# TPTC1 register map
Vendor: Texas Instruments
Peripheral module from a debugger description file (folder omap36xx).
Registers are 32-bit, read-only, reset 0x0 unless marked. A register's access mark holds for its fields unless they carry their own. Offsets are as the file gives them; lines under a group give offsets from that group; [hi:lo] are bit positions; {n}, {i} and the like mark numbered series; 'fields as' and 'values as' point back to an identical list; <NAME> marks a mode.

## TPTC1
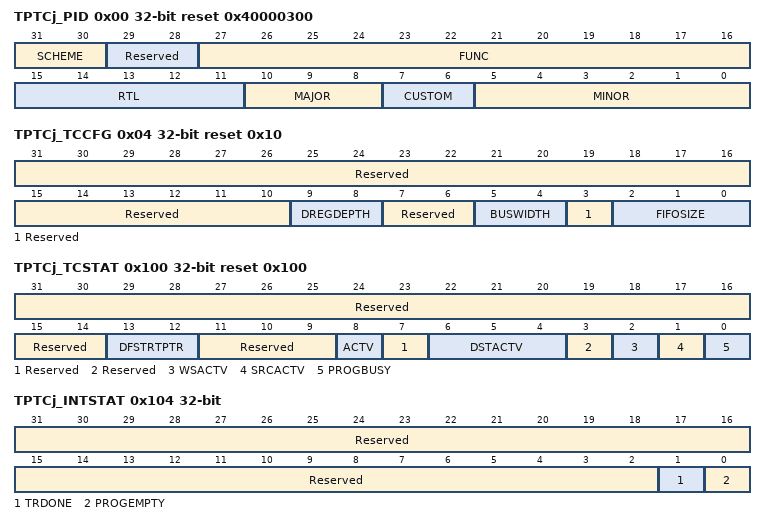
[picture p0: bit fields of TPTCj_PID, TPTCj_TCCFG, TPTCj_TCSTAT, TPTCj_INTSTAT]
0x00 TPTCj_PID access per field reset 0x40000300 (reset mask 0xFFFF07C0) — Peripheral ID Register
  [31:30] SCHEME rw — PID scheme:Used to distinguish between old ID scheme and current.Spare bit to encode future schemes EDMA uses new scheme, indicated with value of 0x1. .
  [29:28] Reserved ro — Read returns 0.
  [27:16] FUNC rw — Function indicates a software-compatible module family.
  [15:11] RTL rw — RTL version
  [10:8] MAJOR rw — Major revision
  [7:6] CUSTOM rw — Custom revision field: Not used on this version of EDMA.
  [5:0] MINOR rw — Minor revision
0x04 TPTCj_TCCFG reset 0x10 (reset mask 0xFFFFFCF8) — TC Configuration Register
  [31:10] Reserved — Read returns 0.
  [9:8] DREGDEPTH — Dst Register FIFO Depth Parameterization
    0=DREGDEPTH_0_r (1 entry); 1=DREGDEPTH_1_r (2 entries); 2=DREGDEPTH_2_r (4 entries)
  [7:6] Reserved — Read returns 0.
  [5:4] BUSWIDTH — Bus Width Parameterization
    0=BUSWIDTH_0_r (32-bit); 1=BUSWIDTH_1_r (64-bit); 2=BUSWIDTH_2_r (128-bit)
  [3] Reserved — Read returns 0.
  [2:0] FIFOSIZE — Fifo Size Parameterization
    0=FIFOSIZE_0_r (32 byte FIFO); 1=FIFOSIZE_1_r (64 byte FIFO); 2=FIFOSIZE_2_r (128 byte FIFO); 3=FIFOSIZE_3_r (256 byte FIFO); 4=FIFOSIZE_4_r (512 byte FIFO)
0x100 TPTCj_TCSTAT reset 0x100 — TC Status Register
  [31:14] Reserved — Read returns 0.
  [13:12] DFSTRTPTR — Dst FIFO Start PointerRepresents the offset to the head entry of Dst Register FIFO, in units of *entries*. Legal values = 0x0 to 0x3
  [11:9] Reserved — Read returns 0.
  [8] ACTV — Channel ActiveChannel Active is a logical-OR of each of the *BUSY/ACTV signals. The ACTV bit must remain high through the life of a TR. ACTV = 0: Channel is idle.ACTV = 1: Channel is busy.
  [7] Reserved — Read returns 0.
  [6:4] DSTACTV — Destination Active StateSpecifies the number of TRs that are resident in the Dst Register FIFO at a given instant. Legal values are constrained by the DSTREGDEPTH parameter.
    0=DSTACTV_0_r (FIFO set is empty.); {v}=DSTACTV_{v}_r (Dst FIFO contains {v} TR) (v=1..4)
  [3] Reserved — Read returns 0.
  [2] WSACTV — Write Status ActiveWSACTV = 0: Write status is not pending. Write status has been received for all previously issued write commands.WSACTV = 1: Write Status is pending. Write status has not been received for all previously issued write commands.
  [1] SRCACTV — Source Active StateSRCACTV = 0: Source Active set is idle. Any TR written to Prog Set will immediately transition to Source Active set as long as the Dst FIFO Set is not full (DSTFULL == 1).SRCACTV = 1: Source Active set is busy either performing read transfers or waiting to perform read transfers for current Transfer Request.
  [0] PROGBUSY — Program Register Set BusyPROGBUSY = 0: Prog set idle and is available for programming.PROGBUSY = 1: Prog set busy. User should poll for PROGBUSY equal to 0 prior to re-programming the Program Register set.
0x104 TPTCj_INTSTAT — Interrupt Status Register
  [31:2] Reserved — Read returns 0.
  [1] TRDONE — TR Done Event Status:TRDONE = 0: Condition not detected.TRDONE = 1: Set when TC has completed a Transfer Request. TRDONE should be set when the write status is returned for the final write of a TR. Cleared when user writes 1 to INTCLR.TRDONE register bit.
  [0] PROGEMPTY — Program Set Empty Event Status:PROGEMPTY = 0: Condition not detected.PROGEMPTY = 1: Set when Program Register set transitions to empty state. Cleared when user writes 1 to INTCLR.PROGEMPTY register bit.
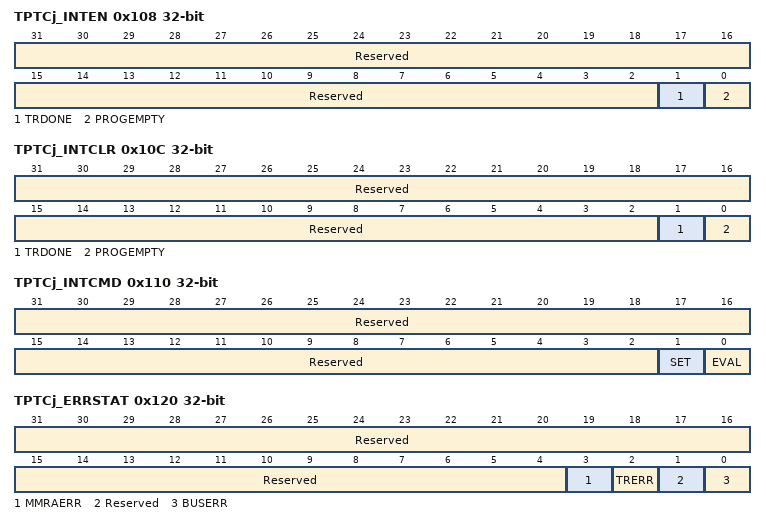
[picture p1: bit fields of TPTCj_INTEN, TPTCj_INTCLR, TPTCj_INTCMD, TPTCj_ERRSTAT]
0x108 TPTCj_INTEN rw — Interrupt Enable Register
  [31:2] Reserved — Write 0s for future compatibility.Read returns 0.
  [1] TRDONE — TR Done Event Enable:INTEN.TRDONE = 0: TRDONE Event is disabled.INTEN.TRDONE = 1: TRDONE Event is enabled,and contributes to interrupt generation
  [0] PROGEMPTY — Program Set Empty Event Enable:INTEN.PROGEMPTY = 0: PROGEMPTY Event isdisabled.INTEN.PROGEMPTY = 1: PROGEMPTY Event isenabled, and contributes to interrupt generation
0x10C TPTCj_INTCLR wo — Interrupt Clear Register
  [31:2] Reserved — Write 0s for future compatibility.
  [1] TRDONE — TR Done Event Clear:INTCLR.TRDONE = 0: Writes of 0 have no effect.INTCLR.TRDONE = 1: Write of 1 clears INTSTAT.TRDONE bit
  [0] PROGEMPTY — Program Set Empty Event Clear:INTCLR.PROGEMPTY = 0: Writes of 0 have no effect.INTCLR.PROGEMPTY = 1: Write of 1 clears INTSTAT.PROGEMPTY bit
0x110 TPTCj_INTCMD wo — Interrupt Command Register
  [31:2] Reserved — Write 0s for future compatibility.
  [1] SET — Set TPTC interrupt:Write of 1 to SET causes TPTC interrupt to be pulsed unconditionally.Writes of 0 have no effect.
  [0] EVAL — Evaluate state of TPTC interruptWrite of 1 to EVAL causes TPTC interrupt to be pulsed if any of the INTSTAT bits are set to 1.Writes of 0 have no effect.
0x120 TPTCj_ERRSTAT — Error Status Register
  [31:4] Reserved — Read returns 0.
  [3] MMRAERR — MMR Address Error:MMRAERR = 0: Condition not detected.MMRAERR = 1: User attempted to read or write to invalid address configuration memory map. (Is only be set for non-emulation accesses). No additional error information is recorded.
  [2] TRERR — TR Error:TR detected that violates FIFO Mode transfer (SAM or DAM is 1) alignment rules or has ACNT or BCNT == 0. No additional error information is recorded.
  [1] Reserved — Read returns 0.
  [0] BUSERR — Bus Error Event:BUSERR = 0: Condition not detected.BUSERR = 1: TC has detected an error code on the write response bus or read response bus. Error information is stored in Error Details Register (ERRDET).
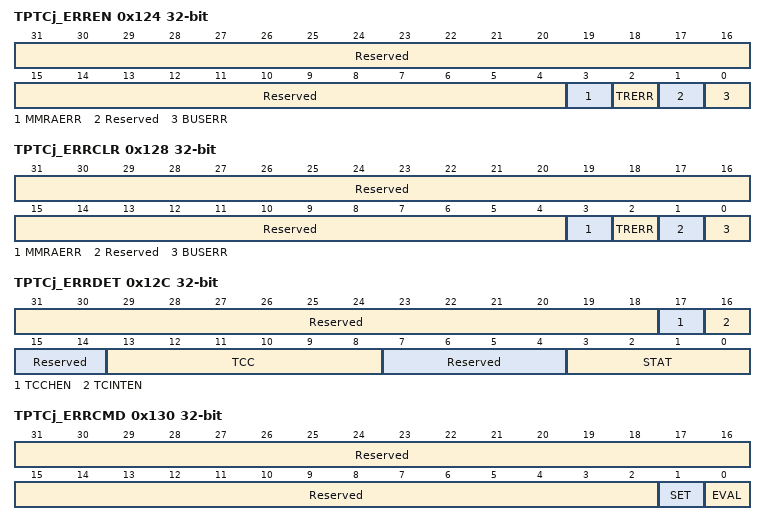
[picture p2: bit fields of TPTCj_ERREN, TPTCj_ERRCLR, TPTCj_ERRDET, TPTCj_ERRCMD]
0x124 TPTCj_ERREN rw — Error Enable Register
  [31:4] Reserved — Write 0s for future compatibility.Read returns 0.
  [3] MMRAERR — Interrupt enable for ERRSTAT.MMRAERR:ERREN.MMRAERR = 0: BUSERR is disabled.ERREN.MMRAERR = 1: MMRAERR is enabled, and contributes to the TPTC error interrupt generation.
  [2] TRERR — Interrupt enable for ERRSTAT.TRERR:ERREN.TRERR = 0: BUSERR is disabled.ERREN.TRERR = 1: TRERR is enabled, andcontributes to the TPTC error interrupt generation.
  [1] Reserved — Write 0s for future compatibility.Read returns 0.
  [0] BUSERR — Interrupt enable for ERRSTAT.BUSERR:ERREN.BUSERR = 0: BUSERR is disabled.ERREN.BUSERR = 1: BUSERR is enabled, andcontributes to the TPTC error interrupt generation.
0x128 TPTCj_ERRCLR wo — Error Clear Register
  [31:4] Reserved — Write 0s for future compatibility.
  [3] MMRAERR — Interrupt clear for ERRSTAT.MMRAERR:ERRCLR.MMRAERR = 0: Writes of 0 have no effect.ERRCLR.MMRAERR = 1: Write of 1 clearsERRSTAT.MMRAERR bit. Write of 1 to ERRCLR.MMRAERR does not clear the ERRDET register.
  [2] TRERR — Interrupt clear for ERRSTAT.TRERR:ERRCLR.TRERR = 0: Writes of 0 have no effect.ERRCLR.TRERR = 1: Write of 1 clears ERRSTAT.TRERR bit. Write of 1 to ERRCLR.TRERR does not clear the ERRDET register.
  [1] Reserved — Write 0s for future compatibility.
  [0] BUSERR — Interrupt clear for ERRSTAT.BUSERR:ERRCLR.BUSERR = 0: Writes of 0 have no effect.ERRCLR.BUSERR = 1: Write of 1 clearsERRSTAT.BUSERR bit. Write of 1 to ERRCLR.BUSERR clears the ERRDET register.
0x12C TPTCj_ERRDET — Error Details Register
  [31:18] Reserved — Read returns 0.
  [17] TCCHEN — Contains the OPT.TCCHEN value programmed by the user for the Read or Write transaction that resulted in an error.
  [16] TCINTEN — Contains the OPT.TCINTEN value programmed by the user for the Read or Write transaction that resulted in an error.
  [15:14] Reserved — Read returns 0.
  [13:8] TCC — Transfer Complete Code:Contains the OPT.TCC value programmed by the user for the Read or Write transaction that resulted in an error.
  [7:4] Reserved — Read returns 0.
  [3:0] STAT — Transaction Status:Stores the non-zero status/error code that was detected on the read status or write status bus. MS-bit effectively serves as the read vs. write error code. If read status and write status are returned on the same cycle, then the TC chooses non-zero version. If both are non-zero then write status is treated as higherpriority.Encoding of errors matches the CBA spec and issummarized here: 0xF =
    0=STAT_0_r (No Error (should not cause error to be latched)); 1=STAT_1_r (Read Addressing error); 2=STAT_2_r (Read Privilege error); 3=STAT_3_r (Read Timeout error); 4=STAT_4_r (Read Data error); 7=STAT_7_r (Read Exclusive-operation failure); 8=STAT_8_r (No Error (should not cause error to be latched)); 9=STAT_9_r (Write Addressing error); 10=STAT_10_r (Write Privilege error); 11=STAT_11_r (Write Timeout error); 12=STAT_12_r (Write Data error); 15=STAT_15_r (Write Exclusive-operation failure)
0x130 TPTCj_ERRCMD wo — Error Command Register
  [31:2] Reserved — Write 0s for future compatibility.
  [1] SET — Set TPTC error interrupt:Write of 1 to SET causes TPTC error interrupt to be pulsed unconditionally.Writes of 0 have no effect.
  [0] EVAL — Evaluate state of TPTC error interruptWrite of 1 to EVAL causes TPTC error interrupt to be pulsed if any of the ERRSTAT bits are set to 1.Writes of 0 have no effect.
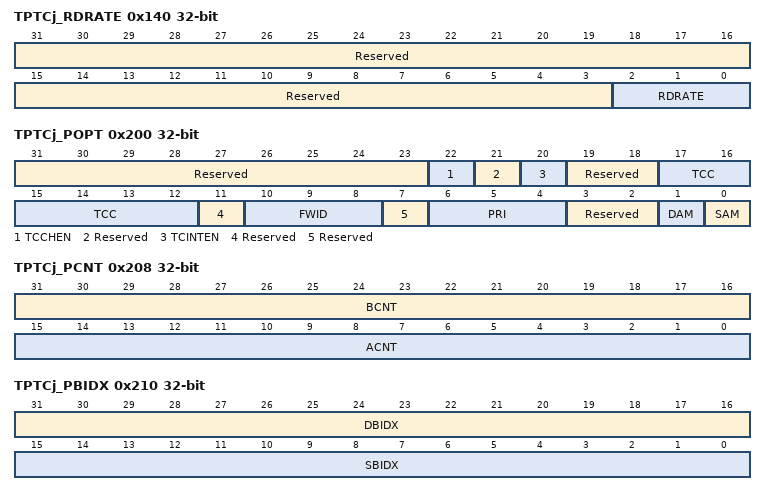
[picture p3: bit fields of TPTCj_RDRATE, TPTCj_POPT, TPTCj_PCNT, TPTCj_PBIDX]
0x140 TPTCj_RDRATE rw — Read Rate Register
  [31:3] Reserved — Write 0s for future compatibility.Read returns 0.
  [2:0] RDRATE — Read Rate Control:Controls the number of cycles between read commands. This is a global setting that applies to all TRs for this TC.
    0=Reads issued as fast as possible; 1=4 cycles between reads; 2=8 cycles between reads; 3=16 cycles between reads; 4=32 cycles between reads
0x200 TPTCj_POPT rw — Prog Set Options
  [31:23] Reserved — Write 0s for future compatibility.Read returns 0.
  [22] TCCHEN — Transfer complete chaining enable:0: Transfer complete chaining is disabled.1: Transfer complete chaining is enabled.
  [21] Reserved — Write 0s for future compatibility.Read returns 0.
  [20] TCINTEN — Transfer complete interrupt enable:0: Transfer complete interrupt is disabled.1: Transfer complete interrupt is enabled.
  [19:18] Reserved — Write 0s for future compatibility.Read returns 0.
  [17:12] TCC — Transfer Complete Code:The 6-bit code is used to set the relevant bit in CER or IPR of the TPCC module.
  [11] Reserved — Write 0s for future compatibility.Read returns 0.
  [10:8] FWID — FIFO width control:Applies if either SAM or DAM is set to FIFO mode.
    0=FIFO width is 8-bit; 1=FIFO width is 16-bit; 2=FIFO width is 32-bit; 3=FIFO width is 64-bit; 4=FIFO width is 128-bit; 5=FIFO width is 256-bit
  [7] Reserved — Write 0s for future compatibility.Read returns 0.
  [6:4] PRI — Transfer Priority:0: Priority 0 - Highest priority1: Priority 1...7: Priority 7 - Lowest priority
    0=Priority 0 - Highest priority; {v}=Priority {v} (v=1..6); 7=Priority 7 - Lowest Priority
  [3:2] Reserved — Write 0s for future compatibility.Read returns 0.
  [1] DAM — Destination Address Mode within an array:0: INCR, Dst addressing within an array increments.1: FIFO, Dst addressing within an array wraps around upon reaching FIFO width.
  [0] SAM — Source Address Mode within an array:0: INCR, Src addressing within an array increments.1: FIFO, Src addressing within an array wraps around upon reaching FIFO width.
0x204 TPTCj_PSRC rw — Prog Set Src Address
  [31:0] SADDR — Source address for Program Register Set
0x208 TPTCj_PCNT rw — Prog Set Count
  [31:16] BCNT — B-Dimension count. Number of arrays to be transferred, where each array is ACNT in length.
  [15:0] ACNT — A-Dimension count. Number of bytes to be transferred in first dimension.
0x20C TPTCj_PDST rw — Prog Set Dst Address
  [31:0] DADDR — Destination address for Program Register Set
0x210 TPTCj_PBIDX rw — Prog Set B-Dim Idx
  [31:16] DBIDX — Dest B-Idx for Program Register Set: B-Idx offset between Destination arrays: Represents the offset in bytes between the starting address of each destination array (recall that there are BCNT arrays of ACNT elements). DBIDX is always used, regardless of whether DAM is Increment or FIFO mode.
  [15:0] SBIDX — Source B-Idx for Program Register Set: B-Idx offset between Source arrays: Represents the offset in bytes between the starting address of each source array (recall that there are BCNT arrays of ACNT elements). SBIDX is always used, regardless of whether SAM is Increment or FIFO mode.
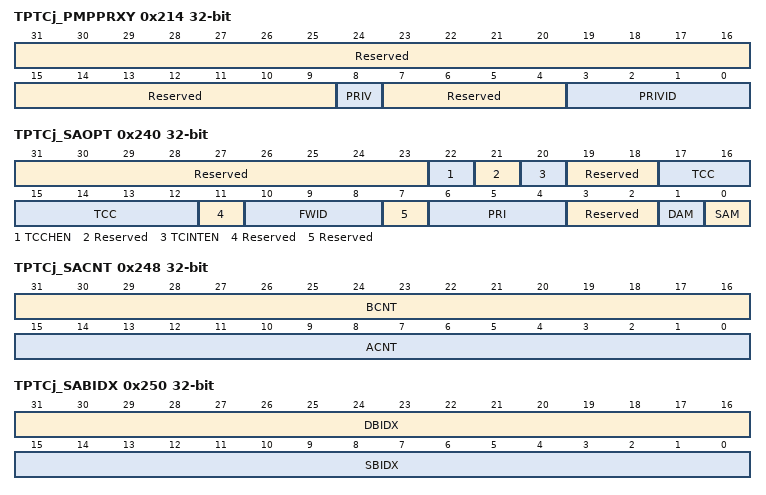
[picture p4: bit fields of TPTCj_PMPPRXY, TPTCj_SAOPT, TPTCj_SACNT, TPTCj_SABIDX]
0x214 TPTCj_PMPPRXY — Prog Set Mem Protect Proxy
  [31:9] Reserved — Read returns 0.
  [8] PRIV — Privilege Level:PRIV = 0: User level privilegePRIV = 1: Supervisor level privilege PMPPRXY.PRIV is always updated with the value from the configuration bus Privilege field on any/every write to Program Set BIDX Register (trigger register). The PRIV value for the SA Set and DF Set are copied from the value in the Program set along with the remainder of the parameter values. The privilege ID is issued on the VBusM read and write command bus such that the target endpoints can perform memory protection checks based on the PRIV of the external host that sets up the DMA transaction.
  [7:4] Reserved — Read returns 0.
  [3:0] PRIVID — Privilege ID: PMPPRXY.PRIVID is always updated with the value from configuration bus Privilege ID field on any/every write to Program Set BIDX Register (trigger register). The PRIVID value for the SA Set and DF Set are copied from the value in the Program set along with the remainder of the parameter values. The privilege ID is issued on the VBusM read and write command bus such that the target endpoints can perform memory protection checks based on the privid of the external host that sets up the DMA transaction.
0x240 TPTCj_SAOPT — Src Actv Set Options
  [31:23] Reserved — Read returns 0.
  [22] TCCHEN — Transfer complete chaining enable:0: Transfer complete chaining is disabled.1: Transfer complete chaining is enabled.
  [21] Reserved — Read returns 0.
  [20] TCINTEN — Transfer complete interrupt enable:0: Transfer complete interrupt is disabled.1: Transfer complete interrupt is enabled.
  [19:18] Reserved — Read returns 0.
  [17:12] TCC — Transfer Complete Code:The 6-bit code is used to set the relevant bit in CER or IPR of the TPCC module.
  [11] Reserved — Read returns 0.
  [10:8] FWID — FIFO width control:Applies if either SAM or DAM is set to FIFO mode.
    0=FWID_0_r (FIFO width is 8-bit); 1=FWID_1_r (FIFO width is 16-bit); 2=FWID_2_r (FIFO width is 32-bit); 3=FWID_3_r (FIFO width is 64-bit); 4=FWID_4_r (FIFO width is 128-bit); 5=FWID_5_r (FIFO width is 256-bit)
  [7] Reserved — Read returns 0.
  [6:4] PRI — Transfer Priority:0: Priority 0 - Highest priority1: Priority 1...7: Priority 7 - Lowest priority
    0=PRI_0_r (Priority 0 - Highest priority); {v}=PRI_{v}_r (Priority {v}) (v=1..6); 7=PRI_7_r (Priority 7 - Lowest Priority)
  [3:2] Reserved — Read returns 0.
  [1] DAM — Destination Address Mode within an array:0: INCR, Dst addressing within an array increments.1: FIFO, Dst addressing within an array wraps around upon reaching FIFO width.
  [0] SAM — Source Address Mode within an array:0: INCR, Src addressing within an array increments.1: FIFO, Src addressing within an array wraps around upon reaching FIFO width.
0x244 TPTCj_SASRC — Src Actv Set Src Address
  [31:0] SADDR — Source address for Source Active Register Set:Initial value is copied from PSRC.SADDR. TC updates value according to source addressing mode (OPT.SAM) and/or source index value (BIDX.SBIDX) after each read command is issued. When a TR is complete, the final value should be the address of the last read command issued.
0x248 TPTCj_SACNT — Src Actv Set Count
  [31:16] BCNT — B-Dimension count:Number of arrays to be transferred, where each array is ACNT in length.Count Remaining for Src Active Register Set. Represents the amount of data remaining to be read. Initial value is copied from PCNT. TC decrements ACNT and BCNT as necessary after each read command isissued. Final value should be 0 when TR is complete.
  [15:0] ACNT — A-Dimension count:Number of bytes to be transferred in first dimension.Count Remaining for Src Active Register Set. Represents the amount of data remaining to be read. Initial value is copied from PCNT. TC decrements ACNT and BCNT as necessary after each read command isissued. Final value should be 0 when TR is complete.
0x24C TPTCj_SADST — rsvd, return 0x0 w/o AERROR
  [31:0] DADDR — Destination address is not applicable for Src Active Register Set.Reads return 0x0
0x250 TPTCj_SABIDX — Src Actv Set B-Dim Idx
  [31:16] DBIDX — Dest B-Idx for Source Active Register Set. Value copied from PBIDX: B-Idx offset between Destination arrays: Represents the offset in bytes between the startingaddress of each destination array (recall that there are BCNT arrays of ACNT elements). DBIDX is always used, regardless of whether DAM is Increment or FIFO mode.
  [15:0] SBIDX — Source B-Idx for Source Active Register Set. Value copied from PBIDX: B-Idx offset between Source arrays: Represents the offset in bytes between the startingaddress of each source array (recall that there are BCNT arrays of ACNT elements). SBIDX is always used, regardless of whether SAM is Increment or FIFO mode.
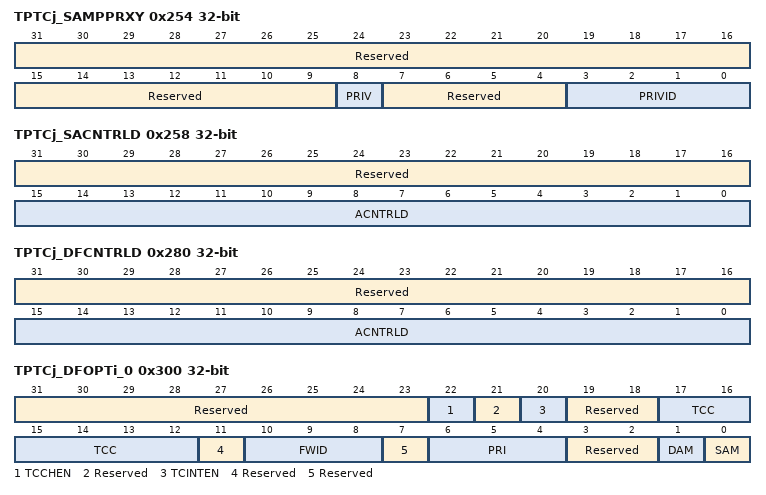
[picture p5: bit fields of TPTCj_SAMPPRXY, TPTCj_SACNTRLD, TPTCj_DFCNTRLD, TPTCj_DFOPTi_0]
0x254 TPTCj_SAMPPRXY — Src Actv Set Mem Protect Proxy
  [31:9] Reserved — Read returns 0.
  [8] PRIV — Privilege Level:PRIV = 0: User level privilegePRIV = 1: Supervisor level privilege SAMPPRXY.PRIV is always updated with the value from the configuration bus Privilege field on any/every write to Program Set BIDX Register (trigger register). The PRIV value for the SA Set and DF Set are copied from the value in the Program set along with the remainder of the parameter values. The privilege ID is issued on the VBusM read and write command bus such that the target endpoints can perform memory protection checks based on the PRIV of the external host that sets up the DMA transaction.
  [7:4] Reserved — Read returns 0.
  [3:0] PRIVID — Privilege ID: SAMPPRXY.PRIVID is always updated with the value from configuration bus Privilege ID field on any/every write to Program Set BIDX Register (trigger register). The PRIVID value for the SA Set and DF Set are copied from the value in the Program set along with the remainder of the parameter values. The privilege ID is issued on the VBusM read and write command bus such that the target endpoints can perform memory protection checks based on the privid of the external host that sets up the DMA transaction.
0x258 TPTCj_SACNTRLD — Src Actv Set Cnt Reload
  [31:16] Reserved — Read returns 0.
  [15:0] ACNTRLD — A-Cnt Reload value for Source Active Register set. Value copied from PCNT.ACNT: Represents the originally programmed value of ACNT. The Reload value is used to reinitialize ACNT after each array is serviced (i.e., ACNT decrements to 0). by the Src offset in bytes between the starting address of each source array (recall that there are BCNT arrays of ACNT bytes)
0x25C TPTCj_SASRCBREF — Src Actv Set Src Addr A-Reference
  [31:0] SADDRBREF — Source address reference for Source Active Register Set: Represents the starting address for the array currently being read. The next arrays starting address is calculated as the reference address plus the source b-idx value.
0x260 TPTCj_SADSTBREF — rsvd, return 0x0 w/o AERROR
  [31:0] DADDRBREF — Dst address reference is not applicable for Src Active Register Set.Reads return 0x0.
0x280 TPTCj_DFCNTRLD — Dst FIFO Set Cnt Reload
  [31:16] Reserved — Read returns 0.
  [15:0] ACNTRLD — A-Cnt Reload value for Destination FIFO Register set. Value copied from PCNT.ACNT: Represents the originally programmed value of ACNT. The Reload value is used to reinitialize ACNT after each array is serviced (i.e., ACNT decrements to 0). by the Src offset in bytes between the starting address of each source array (recall that there are BCNT arrays of ACNT bytes)
0x284 TPTCj_DFSRCBREF — rsvd, return 0x0 w/o AERROR
  [31:0] SADDRBREF — Source address reference is not applicable for Dst FIFO Register Set.Reads return 0x0.
0x288 TPTCj_DFDSTBREF — Dst FIFO Set Dst Addr A-Reference
  [31:0] DADDRBREF — Destination address reference for Dst FIFO Register Set: Represents the starting address for the array currently being written. The next arrays starting address is calculated as the reference address plus the dest bidxvalue.
0x300 TPTCj_DFOPTi_0 — Dst FIFO i Set Options
  fields as TPTCj_SAOPT
0x304 TPTCj_DFSRCi_0 — rsvd, return 0x0 w/o AERROR
  [31:0] SADDR — Source address is not applicable for Dst FIFORegister Set:Reads return 0x0.
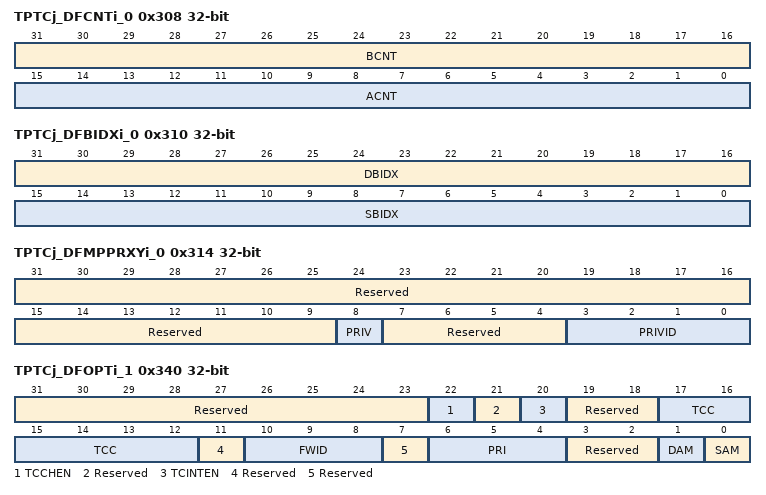
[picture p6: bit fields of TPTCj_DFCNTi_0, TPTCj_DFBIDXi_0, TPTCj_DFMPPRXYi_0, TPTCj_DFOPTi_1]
0x308 TPTCj_DFCNTi_0 — Dst FIFO i Set Count
  [31:16] BCNT — B-Count Remaining for Dst Register Set: Number of arrays to be transferred, where each array is ACNT in length.Represents the amount of data remaining to be written. Initial value is copied from PCNT. TC decrements ACNT and BCNT as necessary after each write dataphase is issued. Final value should be 0 when TR is complete.
  [15:0] ACNT — A-Count Remaining for Dst Register Set: Number of bytes to be transferred in first dimension.Represents the amount of data remaining to be written. Initial value is copied from PCNT. TC decrements ACNT and BCNT as necessary after each write dataphase is issued. Final value should be 0 when TR is complete.
0x30C TPTCj_DFDSTi_0 — Dst FIFO i Set Dst Address
  [31:0] DADDR — Destination address for Dst FIFO Register Set: Initial value is copied from PDST.DADDR. TC updates value according to destination addressing mode (OPT.SAM) and/or dest index value (BIDX.DBIDX) after each write command is issued. When a TR is complete, the final value should be the address of the last write command issued.
0x310 TPTCj_DFBIDXi_0 — Dst FIFO i Set B-Dim Idx
  [31:16] DBIDX — Dest B-Idx for Dest FIFO Register Set. Value copied from PBIDX: B-Idx offset between Destination arrays: Represents the offset in bytes between the startingaddress of each destination array (recall that there are BCNT arrays of ACNT elements). DBIDXi is always used, regardless of whether DAM is Increment or FIFO mode.
  [15:0] SBIDX — Dest B-Idx for Dest FIFO Register Set. Value copied from PBIDX: B-Idx offset between Source arrays: Represents the offset in bytes between the starting address of each source array (recall that there are BCNT arrays of ACNT elements). SBIDX is always used, regardless of whether SAM is Increment or FIFO mode.
0x314 TPTCj_DFMPPRXYi_0 — Dst FIFO i Mem Protect Proxy
  [31:9] Reserved — Read returns 0.
  [8] PRIV — Privilege Level:PRIV = 0: User level privilegePRIV = 1: Supervisor level privilege DFMPPRXYi.PRIV is always updated with the value from the configuration bus Privilege field on any/every write to Program Set BIDX Register (trigger register). The PRIV value for the SA Set and DF Set are copied from the value in the Program set along with the remainder of the parameter values. The privilege ID is issued on the VBusM read and write command bus such that the target endpoints can perform memory protection checks based on the PRIV of the external host that sets up the DMA transaction.
  [7:4] Reserved — Read returns 0.
  [3:0] PRIVID — Privilege ID: DFMPPRXYi.PRIVID is always updated with the value from configuration bus Privilege ID field on any/every write to Program Set BIDX Register (trigger register). The PRIVID value for the SA Set and DF Set are copied from the value in the Program set along with the remainder of the parameter values. The privilege ID is issued on the VBusM read and write command bus such that the target endpoints can perform memory protection checks based on the privid of the external host that sets up the DMA transaction.
0x340 TPTCj_DFOPTi_1 — Dst FIFO i Set Options
  fields as TPTCj_SAOPT
0x344 TPTCj_DFSRCi_1 — rsvd, return 0x0 w/o AERROR
  fields as TPTCj_DFSRCi_0
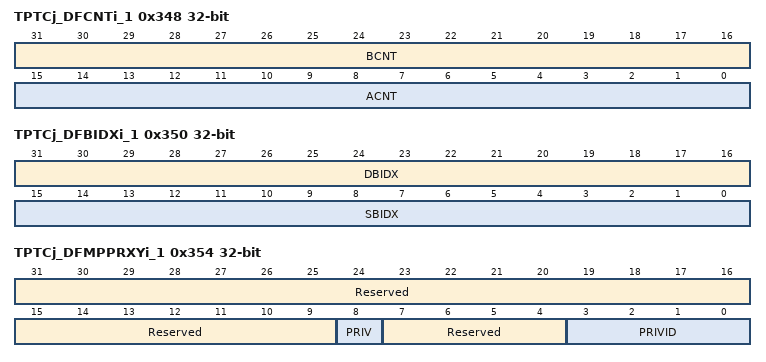
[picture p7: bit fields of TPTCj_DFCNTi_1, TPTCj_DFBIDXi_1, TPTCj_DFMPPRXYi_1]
0x348 TPTCj_DFCNTi_1 — Dst FIFO i Set Count
  fields as TPTCj_DFCNTi_0
0x34C TPTCj_DFDSTi_1 — Dst FIFO i Set Dst Address
  fields as TPTCj_DFDSTi_0
0x350 TPTCj_DFBIDXi_1 — Dst FIFO i Set B-Dim Idx
  fields as TPTCj_DFBIDXi_0
0x354 TPTCj_DFMPPRXYi_1 — Dst FIFO i Mem Protect Proxy
  fields as TPTCj_DFMPPRXYi_0
